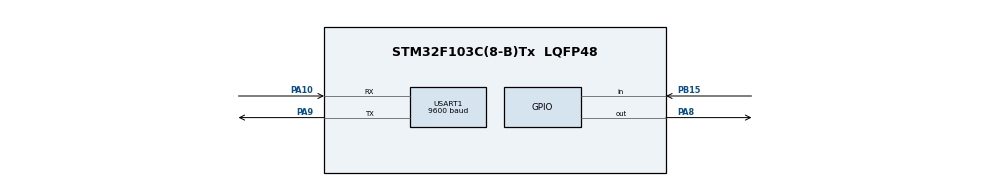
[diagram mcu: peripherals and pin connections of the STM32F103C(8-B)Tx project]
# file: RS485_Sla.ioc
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Mcu.Family=STM32F1
Mcu.Name=STM32F103C(8-B)Tx
Mcu.Package=LQFP48
NVIC.PriorityGroup=NVIC_PRIORITYGROUP_4
NVIC.USART1_IRQn=true\:0\:0\:false\:false\:true\:true\:true\:true
PA10.Mode=Asynchronous
PA10.Signal=USART1_RX
PA8.GPIO_Speed=GPIO_SPEED_FREQ_HIGH
PA8.Signal=GPIO_Output
PA9.Mode=Asynchronous
PA9.Signal=USART1_TX
PB15.GPIO_PuPd=GPIO_PULLUP
PB15.Signal=GPIO_Input
ProjectManager.HeapSize=0x200
ProjectManager.StackSize=0x400
ProjectManager.TargetToolchain=MDK-ARM V5.32
RCC.APB1Freq_Value=8000000
RCC.APB2Freq_Value=8000000
USART1.BaudRate=9600
USART1.VirtualMode=VM_ASYNC
VP_SYS_VS_ND.Mode=No_Debug
board=custom

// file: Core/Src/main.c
/* USER CODE BEGIN Header */
/**
  ******************************************************************************
  * @file           : main.c
  * @brief          : Main program body
  ******************************************************************************
  * @attention
  *
  * Copyright (c) 2026 STMicroelectronics.
  * All rights reserved.
  *
  * This software is licensed under terms that can be found in the LICENSE file
  * in the root directory of this software component.
  * If no LICENSE file comes with this software, it is provided AS-IS.
  *
  ******************************************************************************
  */
/* USER CODE END Header */
#include "main.h"
#include "usart.h"
#include "gpio.h"
#include "stdio.h"
#include "string.h"

void SystemClock_Config(void);

/* USER CODE BEGIN 0 */
uint8_t rx_data[1];

/* USER CODE END 0 */

int main(void)
{

  /* MCU Configuration--------------------------------------------------------*/

  /* Reset of all peripherals, Initializes the Flash interface and the Systick. */
  HAL_Init();

  /* Configure the system clock */
  SystemClock_Config();

  /* Initialize all configured peripherals */
  MX_GPIO_Init();
  MX_USART1_UART_Init();
  /* USER CODE BEGIN 2 */
	HAL_GPIO_WritePin(GPIOA, GPIO_PIN_8, GPIO_PIN_RESET);
HAL_UART_Receive_IT(&huart1,rx_data,1);
  /* USER CODE END 2 */

  /* Infinite loop */
  while (1)
  {

  }
}

void SystemClock_Config(void)
{
  RCC_OscInitTypeDef RCC_OscInitStruct = {0};
  RCC_ClkInitTypeDef RCC_ClkInitStruct = {0};

  /** Initializes the RCC Oscillators according to the specified parameters
  * in the RCC_OscInitTypeDef structure.
  */
  RCC_OscInitStruct.OscillatorType = RCC_OSCILLATORTYPE_HSI;
  RCC_OscInitStruct.HSIState = RCC_HSI_ON;
  RCC_OscInitStruct.HSICalibrationValue = RCC_HSICALIBRATION_DEFAULT;
  RCC_OscInitStruct.PLL.PLLState = RCC_PLL_NONE;
  if (HAL_RCC_OscConfig(&RCC_OscInitStruct) != HAL_OK)
  {
    Error_Handler();
  }

  /** Initializes the CPU, AHB and APB buses clocks
  */
  RCC_ClkInitStruct.ClockType = RCC_CLOCKTYPE_HCLK|RCC_CLOCKTYPE_SYSCLK
                              |RCC_CLOCKTYPE_PCLK1|RCC_CLOCKTYPE_PCLK2;
  RCC_ClkInitStruct.SYSCLKSource = RCC_SYSCLKSOURCE_HSI;
  RCC_ClkInitStruct.AHBCLKDivider = RCC_SYSCLK_DIV1;
  RCC_ClkInitStruct.APB1CLKDivider = RCC_HCLK_DIV1;
  RCC_ClkInitStruct.APB2CLKDivider = RCC_HCLK_DIV1;

  if (HAL_RCC_ClockConfig(&RCC_ClkInitStruct, FLASH_LATENCY_0) != HAL_OK)
  {
    Error_Handler();
  }
}

/* USER CODE BEGIN 4 */
// H�m Callback n�y s? t? d?ng ch?y m?i khi Slave nh?n du?c 1 byte t? Master
void HAL_UART_RxCpltCallback(UART_HandleTypeDef *huart)
{
    if (huart->Instance == USART1)
    {
        // B?n c� th? x? l� d? li?u rx_buffer[0] ? d�y
        // (Trong Proteus, Virtual Terminal n?i v�o PA10 c?a Slave s? t? d?ng in d? li?u n�y ra m�n h�nh)

        // TI?P T?C b?t l?i ng?t d? nh?n c�c byte ti?p theo c?a chu?i "HELLO"
        HAL_UART_Receive_IT(&huart1, rx_data, 1);
    }
}
/* USER CODE END 4 */

void Error_Handler(void)
{
  __disable_irq();
  while (1)
  {
  }
}
